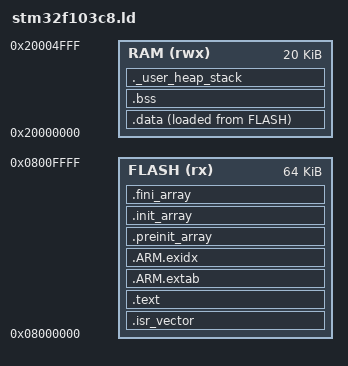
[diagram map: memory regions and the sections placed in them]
/*
 * Linker script for STM32F103C8T6 (64 KiB flash, 20 KiB SRAM).
 * Matches the symbols expected by the CMSIS gcc startup file
 * (startup_stm32f103xb.s): _sidata, _sdata, _edata, _sbss, _ebss, _estack.
 */

ENTRY(Reset_Handler)

MEMORY
{
    FLASH (rx)  : ORIGIN = 0x08000000, LENGTH = 64K
    RAM   (rwx) : ORIGIN = 0x20000000, LENGTH = 20K
}

_estack = ORIGIN(RAM) + LENGTH(RAM);

_Min_Heap_Size  = 0;    /* no heap: bare-metal superloop, static buffers only */
_Min_Stack_Size = 0x400; /* 1 KiB reserved (checked at link time) */

SECTIONS
{
    .isr_vector :
    {
        . = ALIGN(4);
        KEEP(*(.isr_vector))
        . = ALIGN(4);
    } > FLASH

    .text :
    {
        . = ALIGN(4);
        *(.text)
        *(.text*)
        *(.rodata)
        *(.rodata*)
        KEEP(*(.init))
        KEEP(*(.fini))

        . = ALIGN(4);
        _etext = .;
    } > FLASH

    .ARM.extab :
    {
        *(.ARM.extab* .gnu.linkonce.armextab.*)
    } > FLASH

    .ARM.exidx :
    {
        __exidx_start = .;
        *(.ARM.exidx*)
        __exidx_end = .;
    } > FLASH

    .preinit_array :
    {
        PROVIDE_HIDDEN(__preinit_array_start = .);
        KEEP(*(.preinit_array*))
        PROVIDE_HIDDEN(__preinit_array_end = .);
    } > FLASH

    .init_array :
    {
        PROVIDE_HIDDEN(__init_array_start = .);
        KEEP(*(SORT(.init_array.*)))
        KEEP(*(.init_array*))
        PROVIDE_HIDDEN(__init_array_end = .);
    } > FLASH

    .fini_array :
    {
        PROVIDE_HIDDEN(__fini_array_start = .);
        KEEP(*(SORT(.fini_array.*)))
        KEEP(*(.fini_array*))
        PROVIDE_HIDDEN(__fini_array_end = .);
    } > FLASH

    _sidata = LOADADDR(.data);

    .data :
    {
        . = ALIGN(4);
        _sdata = .;
        *(.data)
        *(.data*)
        . = ALIGN(4);
        _edata = .;
    } > RAM AT > FLASH

    .bss (NOLOAD) :
    {
        . = ALIGN(4);
        _sbss = .;
        _ISR_START = .;
        KEEP(*(.isr_ram))
        _ISR_END = .;
        *(.bss)
        *(.bss*)
        *(COMMON)
        . = ALIGN(4);
        _ebss = .;
    } > RAM

    ._user_heap_stack (NOLOAD) :
    {
        . = ALIGN(8);
        PROVIDE(end = .);
        PROVIDE(_end = .);
        . = . + _Min_Heap_Size + _Min_Stack_Size;
        . = ALIGN(8);
    } > RAM

    /DISCARD/ :
    {
        *(.comment)
        *(.note*)
    }

    ASSERT(_end <= (_estack - _Min_Stack_Size), "region RAM overflowed with .data+.bss+stack")
}
